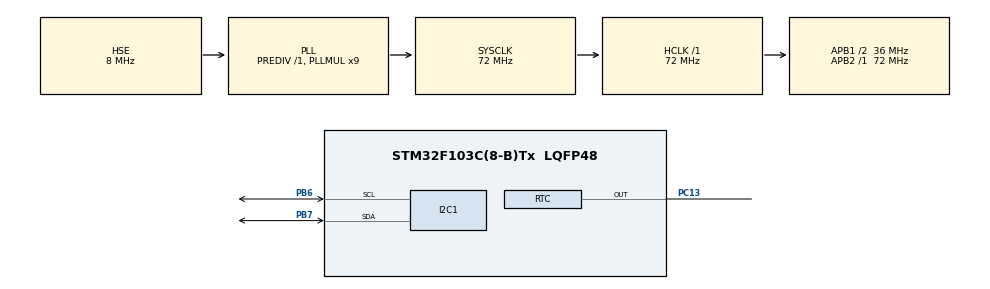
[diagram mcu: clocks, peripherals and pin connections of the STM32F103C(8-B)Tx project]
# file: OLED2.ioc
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I2C1.I2C_Mode=I2C_Fast
Mcu.Family=STM32F1
Mcu.Name=STM32F103C(8-B)Tx
Mcu.Package=LQFP48
NVIC.PriorityGroup=NVIC_PRIORITYGROUP_4
PA13.Mode=Serial_Wire
PA13.Signal=SYS_JTMS-SWDIO
PA14.Mode=Serial_Wire
PA14.Signal=SYS_JTCK-SWCLK
PB6.Mode=I2C
PB6.Signal=I2C1_SCL
PB7.Mode=I2C
PB7.Signal=I2C1_SDA
PC13-TAMPER-RTC.Mode=RTC OUT
PC13-TAMPER-RTC.Signal=RTC_OUT
PD0-OSC_IN.Mode=HSE-External-Oscillator
PD0-OSC_IN.Signal=RCC_OSC_IN
PD1-OSC_OUT.Mode=HSE-External-Oscillator
PD1-OSC_OUT.Signal=RCC_OSC_OUT
ProjectManager.HeapSize=0x200
ProjectManager.StackSize=0x400
ProjectManager.TargetToolchain=STM32CubeIDE
RCC.AHBFreq_Value=72000000
RCC.APB1CLKDivider=RCC_HCLK_DIV2
RCC.APB1Freq_Value=36000000
RCC.APB1TimFreq_Value=72000000
RCC.APB2Freq_Value=72000000
RCC.APB2TimFreq_Value=72000000
RCC.HCLKFreq_Value=72000000
RCC.PLLMUL=RCC_PLL_MUL9
RCC.PLLSourceVirtual=RCC_PLLSOURCE_HSE
RCC.SYSCLKFreq_VALUE=72000000
RCC.SYSCLKSource=RCC_SYSCLKSOURCE_PLLCLK
RCC.USBFreq_Value=72000000
RTC.Format=RTC_FORMAT_BIN
RTC.Hours=22
RTC.Hours_A-RTC\ OUT=9
RTC.Minutes=12
RTC.Month=RTC_MONTH_JULY
RTC.Seconds_A-RTC\ OUT=1
RTC.Year=24
VP_RTC_VS_RTC_Activate.Mode=RTC_Enabled
VP_RTC_VS_RTC_Calendar.Mode=RTC_Calendar
board=custom

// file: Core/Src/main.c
/* USER CODE BEGIN Header */
/**
  ******************************************************************************
  * @file           : main.c
  * @brief          : Main program body
  ******************************************************************************
  * @attention
  *
  * Copyright (c) 2024 STMicroelectronics.
  * All rights reserved.
  *
  * This software is licensed under terms that can be found in the LICENSE file
  * in the root directory of this software component.
  * If no LICENSE file comes with this software, it is provided AS-IS.
  *
  ******************************************************************************
  */
/* USER CODE END Header */
#include "main.h"

/* USER CODE BEGIN Includes */
#include "ssd1306.h"
#include "fonts.h"
#include "test.h"
/* USER CODE END Includes */

/* USER CODE BEGIN PD */
#define CENTER_Pin GPIO_PIN_13
#define CENTER_GPIO_Port GPIOC

/* USER CODE END PD */

I2C_HandleTypeDef hi2c1;

RTC_HandleTypeDef hrtc;

/* USER CODE BEGIN PV */

uint8_t time[10];
uint8_t date[10];
uint8_t day[10];
uint8_t today_1[10]="Monday";
uint8_t today_2[10]="Tuesday";
uint8_t today_3[10]="Wednesday";
uint8_t today_4[10]="Thursday";
uint8_t today_5[10]="Friday";
uint8_t today_6[10]="Saturday";
uint8_t today_7[10]="Sunday";
uint8_t alarm=0;
uint8_t adc_res=0;
uint8_t adc_val=0;
GPIO_PinState buttonState = GPIO_PIN_RESET;
GPIO_PinState lastButtonState = GPIO_PIN_RESET;
uint32_t buttonPressTime = 0;
int flag = 0;
uint8_t x=1;
uint16_t sensor1_data, sensor2_data, sensor3_data,sensor4_data;

/* USER CODE END PV */

void SystemClock_Config(void);
static void MX_GPIO_Init(void);
static void MX_I2C1_Init(void);
static void MX_RTC_Init(void);

/* USER CODE BEGIN 0 */

//void set_time(void)
//{
//	RTC_TimeTypeDef sTime = {0};
//	RTC_DateTypeDef sDate = {0};
//
//	sTime.Hours = 0x10;
//	  sTime.Minutes = 0x35;
//	  sTime.Seconds = 0x40;
//	  sTime.DayLightSaving = RTC_DAYLIGHTSAVING_NONE;
//	  sTime.StoreOperation = RTC_STOREOPERATION_RESET;
//	  if (HAL_RTC_SetTime(&hrtc, &sTime, RTC_FORMAT_BCD) != HAL_OK)
//	  {
//	    Error_Handler();
//	  }
//
//	  sDate.WeekDay = RTC_WEEKDAY_TUESDAY;
//	    sDate.Month = RTC_MONTH_MAY;
//	    sDate.Date = 0x16;
//	    sDate.Year = 0x0;
//
//	    if (HAL_RTC_SetDate(&hrtc, &sDate, RTC_FORMAT_BCD) != HAL_OK)
//	    {
//	      Error_Handler();
//	    }
//	    HAL_RTCEx_BKUPWrite(&hrtc , RTC_BKP_DR1, 0x32F2);
//
//}
uint8_t day_function(void)
{
	if(day[0]==48&&day[1]==49)
	  {
		  memcpy(day,today_1,sizeof(day));

	  }
	  if(day[0]==48&&day[1]==50)
	    {
	  	  memcpy(day,today_2,sizeof(day));

	    }
	  if(day[0]==48&&day[1]==51)
	    {
	  	  memcpy(day,today_3,sizeof(day));

	    }
	  if(day[0]==48&&day[1]==52)
	    {
	  	  memcpy(day,today_4,sizeof(day));

	    }
	  if(day[0]==48&&day[1]==53)
	    {
	  	  memcpy(day,today_5,sizeof(day));

	    }
	  if(day[0]==48&&day[1]==54)
	    {
	  	  memcpy(day,today_6,sizeof(day));

	    }
	  if(day[0]==48&&day[1]==55)
	    {
	  	  memcpy(day,today_7,sizeof(day));

	    }
	  return day;
}

void get_time(void)
{
  RTC_DateTypeDef gDate;
  RTC_TimeTypeDef gTime;

  /* Get the RTC current Time */
  HAL_RTC_GetTime(&hrtc, &gTime, RTC_FORMAT_BIN);
  /* Get the RTC current Date */
  HAL_RTC_GetDate(&hrtc, &gDate, RTC_FORMAT_BIN);

  /* Display time Format: hh:mm:ss */
  sprintf((char*)time,"%02d:%02d:%02d",gTime.Hours, gTime.Minutes, gTime.Seconds);

  /* Display date Format: mm-dd-yy */
  sprintf((char*)date,"%02d-%02d-%2d",gDate.Date, gDate.Month, 2000 + gDate.Year);  // I like the date first
  sprintf((char*)day,"%02d",gDate.WeekDay);
  day_function();
}

//void home_screen(void)
//{
//	/* USER CODE END WHILE */
//	  get_time();
//	  SSD1306_GotoXY (15, 25);
//	  SSD1306_Puts (time, &Font_11x18, 1);
//
//	  SSD1306_GotoXY (0, 0);
//	  SSD1306_Puts (date, &Font_7x10, 1);
//
//	  SSD1306_GotoXY (10, 10);
//	  SSD1306_Puts (day, &Font_7x10, 1);
//	  SSD1306_UpdateScreen(); //display
//	  HAL_Delay (200);
//}

/* USER CODE END 0 */

int main(void)
{

  /* MCU Configuration--------------------------------------------------------*/

  /* Reset of all peripherals, Initializes the Flash interface and the Systick. */
  HAL_Init();

  /* Configure the system clock */
  SystemClock_Config();

  /* Initialize all configured peripherals */
  MX_GPIO_Init();
  MX_I2C1_Init();
  MX_RTC_Init();
  /* USER CODE BEGIN 2 */

  SSD1306_Init();

//	if(HAL_RTCEx_BKUPRead(&hrtc, RTC_BKP_DR1)!= 0x32F2)
//	{
//		set_time();
//	}
//    set_alarm();

  /* USER CODE END 2 */

  /* Infinite loop */
  while (1)
  {

    /* USER CODE BEGIN 3 */
	// ==== get time =========
	  RTC_DateTypeDef gDate;
	  RTC_TimeTypeDef gTime;

	  /* Get the RTC current Time */
	  HAL_RTC_GetTime(&hrtc, &gTime, RTC_FORMAT_BIN);
	  /* Get the RTC current Date */
	  HAL_RTC_GetDate(&hrtc, &gDate, RTC_FORMAT_BIN);

	  /* Display time Format: hh:mm:ss */
	  sprintf((char*)time,"%02d:%02d:%02d",gTime.Hours, gTime.Minutes, gTime.Seconds);

	  /* Display date Format: mm-dd-yy */
	  sprintf((char*)date,"%02d-%02d-%2d",gDate.Date, gDate.Month, 2000 + gDate.Year);  // I like the date first
	  sprintf((char*)day,"%02d",gDate.WeekDay);
//	  day_function();

	  // ===== show time ======
	  SSD1306_GotoXY (15, 25);
	  SSD1306_Puts (time, &Font_11x18, 1);
	  SSD1306_UpdateScreen(); //display

	  SSD1306_GotoXY (0, 0);
	  SSD1306_Puts (date, &Font_7x10, 1);
	  SSD1306_UpdateScreen(); //display

//	  SSD1306_GotoXY (10, 10);
//	  SSD1306_Puts (day, &Font_7x10, 1);
//	  SSD1306_UpdateScreen(); //display
//	  HAL_Delay (200);

	// ==== Scan keypad and check for key press ====
//	key_pressed = keypad_scan();
//	if(key_pressed != 0)
//	{
//		SSD1306_GotoXY(0, 30);
//		SSD1306_Putc(key_pressed, &Font_7x10, 1);
//		SSD1306_UpdateScreen();
//		HAL_GPIO_TogglePin(GPIOC, LED_Pin);
//	}
//	HAL_Delay(20);

	  // =========== Test OLED ================
//	  SSD1306_GotoXY(0, 15);
//	  SSD1306_Puts("Count", &Font_7x10, 1);
//	  SSD1306_UpdateScreen();
//	  SSD1306_GotoXY(2, 15*2);
//
//	  char intTostr[20];
//
//	  sprintf(intTostr, "%d", count++);
//
//	  SSD1306_Puts(intTostr, &Font_7x10, 1);
//	  SSD1306_UpdateScreen();
//	  HAL_Delay(10);

//	  // ======= Test blink LED ============
//	  HAL_GPIO_TogglePin(GPIOC, LED_Pin);
//	  HAL_Delay(100);

  }
  /* USER CODE END 3 */
}

void SystemClock_Config(void)
{
  RCC_OscInitTypeDef RCC_OscInitStruct = {0};
  RCC_ClkInitTypeDef RCC_ClkInitStruct = {0};
  RCC_PeriphCLKInitTypeDef PeriphClkInit = {0};

  /** Initializes the RCC Oscillators according to the specified parameters
  * in the RCC_OscInitTypeDef structure.
  */
  RCC_OscInitStruct.OscillatorType = RCC_OSCILLATORTYPE_LSI|RCC_OSCILLATORTYPE_HSE;
  RCC_OscInitStruct.HSEState = RCC_HSE_ON;
  RCC_OscInitStruct.HSEPredivValue = RCC_HSE_PREDIV_DIV1;
  RCC_OscInitStruct.HSIState = RCC_HSI_ON;
  RCC_OscInitStruct.LSIState = RCC_LSI_ON;
  RCC_OscInitStruct.PLL.PLLState = RCC_PLL_ON;
  RCC_OscInitStruct.PLL.PLLSource = RCC_PLLSOURCE_HSE;
  RCC_OscInitStruct.PLL.PLLMUL = RCC_PLL_MUL9;
  if (HAL_RCC_OscConfig(&RCC_OscInitStruct) != HAL_OK)
  {
    Error_Handler();
  }

  /** Initializes the CPU, AHB and APB buses clocks
  */
  RCC_ClkInitStruct.ClockType = RCC_CLOCKTYPE_HCLK|RCC_CLOCKTYPE_SYSCLK
                              |RCC_CLOCKTYPE_PCLK1|RCC_CLOCKTYPE_PCLK2;
  RCC_ClkInitStruct.SYSCLKSource = RCC_SYSCLKSOURCE_PLLCLK;
  RCC_ClkInitStruct.AHBCLKDivider = RCC_SYSCLK_DIV1;
  RCC_ClkInitStruct.APB1CLKDivider = RCC_HCLK_DIV2;
  RCC_ClkInitStruct.APB2CLKDivider = RCC_HCLK_DIV1;

  if (HAL_RCC_ClockConfig(&RCC_ClkInitStruct, FLASH_LATENCY_2) != HAL_OK)
  {
    Error_Handler();
  }
  PeriphClkInit.PeriphClockSelection = RCC_PERIPHCLK_RTC;
  PeriphClkInit.RTCClockSelection = RCC_RTCCLKSOURCE_LSI;
  if (HAL_RCCEx_PeriphCLKConfig(&PeriphClkInit) != HAL_OK)
  {
    Error_Handler();
  }
}

static void MX_I2C1_Init(void)
{

  hi2c1.Instance = I2C1;
  hi2c1.Init.ClockSpeed = 400000;
  hi2c1.Init.DutyCycle = I2C_DUTYCYCLE_2;
  hi2c1.Init.OwnAddress1 = 0;
  hi2c1.Init.AddressingMode = I2C_ADDRESSINGMODE_7BIT;
  hi2c1.Init.DualAddressMode = I2C_DUALADDRESS_DISABLE;
  hi2c1.Init.OwnAddress2 = 0;
  hi2c1.Init.GeneralCallMode = I2C_GENERALCALL_DISABLE;
  hi2c1.Init.NoStretchMode = I2C_NOSTRETCH_DISABLE;
  if (HAL_I2C_Init(&hi2c1) != HAL_OK)
  {
    Error_Handler();
  }

}

static void MX_RTC_Init(void)
{

  RTC_TimeTypeDef sTime = {0};
  RTC_DateTypeDef DateToUpdate = {0};
  RTC_AlarmTypeDef sAlarm = {0};

  /** Initialize RTC Only
  */
  hrtc.Instance = RTC;
  hrtc.Init.AsynchPrediv = RTC_AUTO_1_SECOND;
  hrtc.Init.OutPut = RTC_OUTPUTSOURCE_ALARM;
  if (HAL_RTC_Init(&hrtc) != HAL_OK)
  {
    Error_Handler();
  }

  /** Initialize RTC and set the Time and Date
  */
  sTime.Hours = 22;
  sTime.Minutes = 12;
  sTime.Seconds = 0;

  if (HAL_RTC_SetTime(&hrtc, &sTime, RTC_FORMAT_BIN) != HAL_OK)
  {
    Error_Handler();
  }
  DateToUpdate.WeekDay = RTC_WEEKDAY_MONDAY;
  DateToUpdate.Month = RTC_MONTH_JULY;
  DateToUpdate.Date = 1;
  DateToUpdate.Year = 24;

  if (HAL_RTC_SetDate(&hrtc, &DateToUpdate, RTC_FORMAT_BIN) != HAL_OK)
  {
    Error_Handler();
  }

  /** Enable the Alarm A
  */
  sAlarm.AlarmTime.Hours = 9;
  sAlarm.AlarmTime.Minutes = 0;
  sAlarm.AlarmTime.Seconds = 1;
  sAlarm.Alarm = RTC_ALARM_A;
  if (HAL_RTC_SetAlarm(&hrtc, &sAlarm, RTC_FORMAT_BIN) != HAL_OK)
  {
    Error_Handler();
  }

}

static void MX_GPIO_Init(void)
{

  /* GPIO Ports Clock Enable */
  __HAL_RCC_GPIOC_CLK_ENABLE();
  __HAL_RCC_GPIOD_CLK_ENABLE();
  __HAL_RCC_GPIOA_CLK_ENABLE();
  __HAL_RCC_GPIOB_CLK_ENABLE();

}

void Error_Handler(void)
{
  __disable_irq();
  while (1)
  {
  }
}
